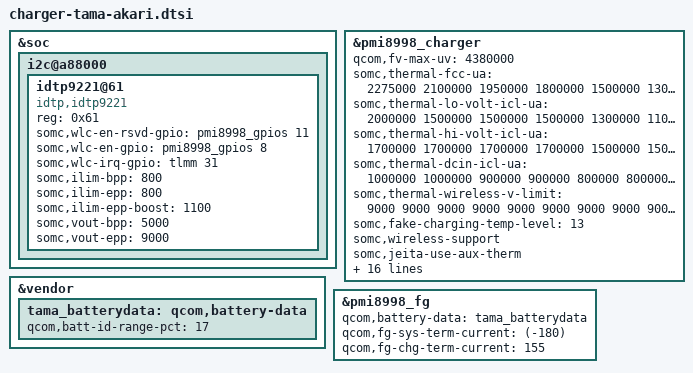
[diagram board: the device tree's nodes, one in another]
// SPDX-License-Identifier: GPL-2.0-only
/*
 * Copyright (c) 2015-2017, The Linux Foundation. All rights reserved.
 */

&soc {
	/* I2C: QUP10 - WLC */
	i2c@a88000 {
		#address-cells = <1>;
		#size-cells = <0>;

		idtp9221@61 {
			compatible = "idtp,idtp9221";
			reg = <0x61>;
			status = "ok";
			somc,wlc-en-rsvd-gpio = <&pmi8998_gpios 11 0>;
			somc,wlc-en-gpio = <&pmi8998_gpios 8 0>;
			somc,wlc-irq-gpio = <&tlmm 31 0>;
			somc,ilim-bpp = <800>;
			somc,ilim-epp = <800>;
			somc,ilim-epp-boost = <1100>;
			somc,vout-bpp = <5000>;
			somc,vout-epp = <9000>;
		};
	};

};

&pmi8998_charger {
	qcom,fv-max-uv = <4380000>;
	somc,thermal-fcc-ua = <2275000 2100000 1950000
				1800000 1500000 1300000
				1300000 1000000 800000
				700000 500000 200000
				100000 0 0>;
	somc,thermal-lo-volt-icl-ua = <2000000 1500000 1500000
					1500000 1300000 1100000
					1100000 1000000 900000
					900000 500000 200000
					100000 0 0>;
	somc,thermal-hi-volt-icl-ua = <1700000 1700000 1700000
					1700000 1500000 1500000
					1000000 1000000 1000000
					600000 500000 200000
					100000 0 0>;
	somc,thermal-dcin-icl-ua = <1000000 1000000 900000
					900000 800000 800000
					700000 600000 500000
					400000 300000 200000
					100000 0 0>;
	somc,thermal-wireless-v-limit = <9000 9000 9000
					9000 9000 9000
					9000 9000 9000
					9000 5000 5000
					5000 5000 5000>;
	somc,fake-charging-temp-level = <13>;
	somc,wireless-support;
	somc,jeita-use-aux-therm;
	somc,jeita-use-wlc-therm;
	somc,jeita-aux-thresh-hot = <900>;
	somc,jeita-aux-thresh-warm = <700>;
	somc,jeita-wlc-thresh-hot = <580>;
	somc,jeita-wlc-thresh-warm = <480>;
	somc,jeita-warm-fcc-ua = <900000>;
	somc,jeita-cool-fcc-ua = <900000>;
	somc,jeita-warm-fv-uv = <4147000>;
	somc,product-icl-ua = <2000000>;
	somc,high-voltage-icl-ua = <1700000>;
	qcom,dc-icl-ua = <1000000>;
	somc,dc-h-volt-boost-icl-ua = <1000000>;
	somc,dc-h-volt-icl-ua = <700000>;
	somc,dc-l-volt-icl-ua = <700000>;
	somc,batt-temp-correction = <0>;
	somc,wlc-temp-correction = <(-30)>;
};

&vendor {
	tama_batterydata: qcom,battery-data {
		qcom,batt-id-range-pct = <17>;
		#include "fg-gen3-batterydata-akari-tmm-4380mv.dtsi"
		#include "fg-gen3-batterydata-akari-tmm-4340mv.dtsi"
		#include "fg-gen3-batterydata-akari-tmm-4300mv.dtsi"
		#include "fg-gen3-batterydata-akari-tmm-4250mv.dtsi"
		#include "fg-gen3-batterydata-akari-byd-4380mv.dtsi"
		#include "fg-gen3-batterydata-akari-byd-4340mv.dtsi"
		#include "fg-gen3-batterydata-akari-byd-4300mv.dtsi"
		#include "fg-gen3-batterydata-akari-byd-4250mv.dtsi"
	};
};

&pmi8998_fg {
	qcom,battery-data = <&tama_batterydata>;
	qcom,fg-sys-term-current = <(-180)>;
	qcom,fg-chg-term-current = <155>;
};
